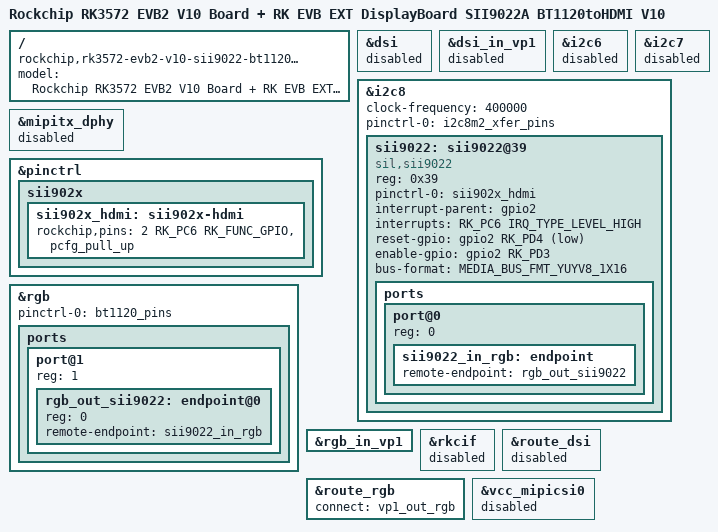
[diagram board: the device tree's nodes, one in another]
// SPDX-License-Identifier: (GPL-2.0+ OR MIT)
/*
 * Copyright (c) 2026 Rockchip Electronics Co., Ltd.
 */

/dts-v1/;

#include <dt-bindings/display/media-bus-format.h>
#include "rk3572-evb2-v10.dtsi"
#include "rk3572-android.dtsi"

/ {
	model = "Rockchip RK3572 EVB2 V10 Board + RK EVB EXT DisplayBoard SII9022A BT1120toHDMI V10";
	compatible = "rockchip,rk3572-evb2-v10-sii9022-bt1120-to-hdmi", "rockchip,rk3572";
};

&dsi {
	status = "disabled";
};

&dsi_in_vp1 {
	status = "disabled";
};

/*
 * The pins of i2c6 and i2c8 are multiplexed
 */
&i2c6 {
	status = "disabled";
};

/*
 * The devices on i2c7 have pins multiplexed with sii9022
 */
&i2c7 {
	status = "disabled";
};

&i2c8 {
	clock-frequency = <400000>;
	pinctrl-0 = <&i2c8m2_xfer_pins>;
	status = "okay";

	sii9022: sii9022@39 {
		compatible = "sil,sii9022";
		reg = <0x39>;
		pinctrl-names = "default";
		pinctrl-0 = <&sii902x_hdmi>;
		interrupt-parent = <&gpio2>;
		interrupts = <RK_PC6 IRQ_TYPE_LEVEL_HIGH>;
		reset-gpio = <&gpio2 RK_PD4 GPIO_ACTIVE_LOW>;
		enable-gpio = <&gpio2 RK_PD3 GPIO_ACTIVE_HIGH>;
		/*
		 * MEDIA_BUS_FMT_YUYV8_1X16 for bt1120
		 * MEDIA_BUS_FMT_UYVY8_2X8  for bt656
		 */
		bus-format = <MEDIA_BUS_FMT_YUYV8_1X16>;
		status = "okay";

		ports {
			#address-cells = <1>;
			#size-cells = <0>;

			port@0 {
				reg = <0>;

				sii9022_in_rgb: endpoint {
					remote-endpoint = <&rgb_out_sii9022>;
				};
			};
		};
	};
};

&mipitx_dphy {
	status = "disabled";
};

&pinctrl {
	sii902x {
		sii902x_hdmi: sii902x-hdmi {
			rockchip,pins = <2 RK_PC6 RK_FUNC_GPIO &pcfg_pull_up>;
		};
	};
};

&rgb {
	status = "okay";
	pinctrl-names = "default";
	/*
	 * <&bt1120_pins> for bt1120
	 * <&bt656_pins>  for bt656
	 */
	pinctrl-0 = <&bt1120_pins>;

	ports {
		port@1 {
			reg = <1>;
			#address-cells = <1>;
			#size-cells = <0>;

			rgb_out_sii9022: endpoint@0 {
				reg = <0>;
				remote-endpoint = <&sii9022_in_rgb>;
			};
		};
	};
};

&rgb_in_vp1 {
	status = "okay";
};

/*
 * The pins of rkcif and lcdc are multiplexed
 */
&rkcif {
	status = "disabled";
};

&route_dsi {
	status = "disabled";
};

&route_rgb {
	status = "okay";
	connect = <&vp1_out_rgb>;
};

/*
 * The pins of vcc_mipicsi0 and sii9022 are multiplexed
 */
&vcc_mipicsi0 {
	status = "disabled";
};
